# MDR1206AFI register map
Vendor: Milandr; File version: 1.0
CPU: BM-310S0, little endian
Registers are 32-bit, read-write, reset 0x0 unless marked. A register's access mark holds for its fields unless they carry their own. Offsets are from the block's base; [hi:lo] are bit positions; {n}, {i} and the like mark numbered series; 'fields as' and 'values as' point back to an identical list.

## BKP — BKP description
Base 0x50060000
0x00 WPR — WPR description
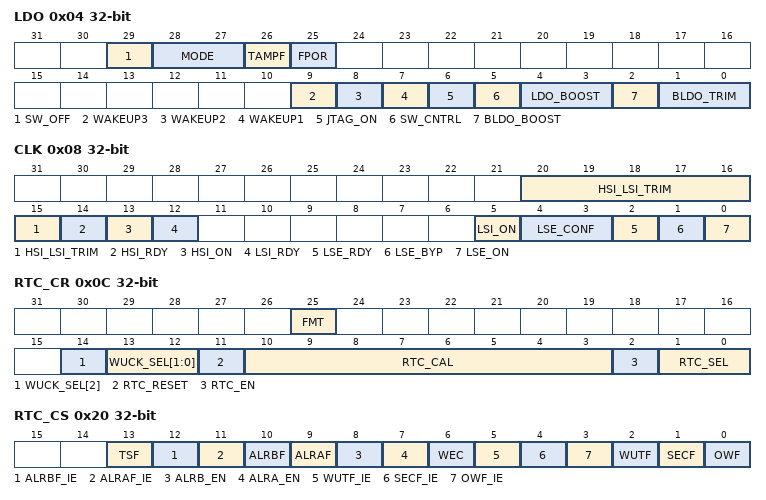
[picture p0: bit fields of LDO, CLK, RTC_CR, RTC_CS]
0x04 LDO — LDO description
  [29] SW_OFF — SW_OFF description
  [28:27] MODE — MODE description
  [26] TAMPF — TAMPF description
  [25] FPOR — FPOR description
  [9] WAKEUP3 ro — WAKEUP3 description
  [8] WAKEUP2 ro — WAKEUP2 description
  [7] WAKEUP1 ro — WAKEUP1 description
  [6] JTAG_ON — JTAG_ON description
  [5] SW_CNTRL — SW_CNTRL description
  [4:3] LDO_BOOST — LDO_BOOST description
  [2] BLDO_BOOST — BLDO_BOOST description
  [1:0] BLDO_TRIM — BLDO_TRIM description
0x08 CLK — CLK description
  [20:15] HSI_LSI_TRIM — HSI_LSI_TRIM description
  [14] HSI_RDY ro — HSI_RDY description
  [13] HSI_ON — HSI_ON description
  [12] LSI_RDY ro — LSI_RDY description
  [5] LSI_ON — LSI_ON description
  [4:3] LSE_CONF — LSE_CONF description
  [2] LSE_RDY ro — LSE_RDY description
  [1] LSE_BYP — LSE_BYP description
  [0] LSE_ON — LSE_ON description
0x0C RTC_CR — RTC_CR description
  [25] FMT — FMT description
  [14] WUCK_SEL[2] — WUCK_SEL[2] description
  [13:12] WUCK_SEL[1:0] — WUCK_SEL[1:0] description
  [11] RTC_RESET — RTC_RESET description
  [10:3] RTC_CAL — RTC_CAL description
  [2] RTC_EN — RTC_EN description
  [1:0] RTC_SEL — RTC_SEL description
0x10 RTC_WUTR — RTC_WUTR description
0x14 RTC_PREDIV_S — RTC_PREDIV_S description
  [19:0] RTC_DIV — RTC_DIV description
0x18 RTC_PRL — RTC_PRL description
  [19:0] RTC_PRL
0x1C RTC_ALRM — RTC_ALRM description
0x20 RTC_CS — RTC_CS description
  [13] TSF — TSF description
  [12] ALRBF_IE — ALRBF_IE description
  [11] ALRAF_IE — ALRAF_IE description
  [10] ALRBF — ALRBF description
  [9] ALRAF — ALRAF description
  [8] ALRB_EN — ALRB_EN description
  [7] ALRA_EN — ALRA_EN description
  [6] WEC ro — WEC description
  [5] WUTF_IE — WUTF_IE description
  [4] SECF_IE — SECF_IE description
  [3] OWF_IE — OWF_IE description
  [2] WUTF — WUTF description
  [1] SECF — SECF description
  [0] OWF — OWF description
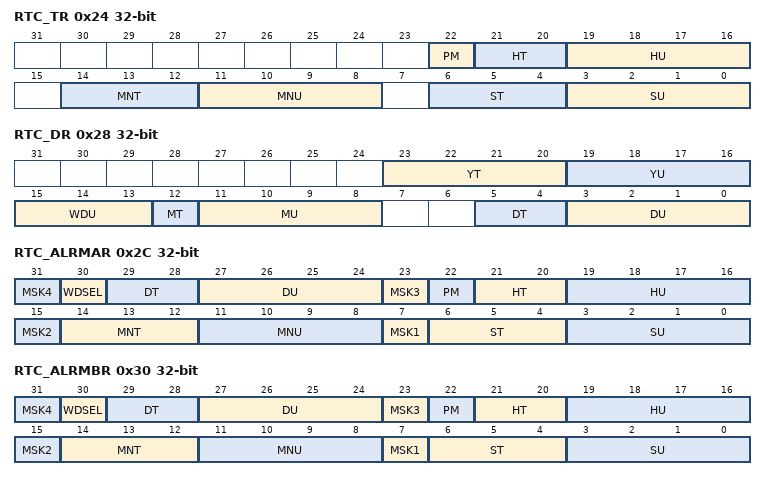
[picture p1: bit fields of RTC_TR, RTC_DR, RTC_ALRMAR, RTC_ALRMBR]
0x24 RTC_TR — RTC_TR description
  [22] PM — PM description
  [21:20] HT — HT description
  [19:16] HU — HU description
  [14:12] MNT — MNT description
  [11:8] MNU — MNU description
  [6:4] ST — ST description
  [3:0] SU — SU description
0x28 RTC_DR — RTC_DR description
  [23:20] YT — YT description
  [19:16] YU — YU description
  [15:13] WDU — WDU description
  [12] MT — MT description
  [11:8] MU — MU description
  [5:4] DT — DT description
  [3:0] DU — DU description
0x2C RTC_ALRMAR — RTC_ALRMAR description
  [8n-1] MSK{n} (n=1..4) — MSK{n} description
  [30] WDSEL — WDSEL description
  [29:28] DT — DT description
  [27:24] DU — DU description
  [22] PM — PM description
  [21:20] HT — HT description
  [19:16] HU — HU description
  [14:12] MNT — MNT description
  [11:8] MNU — MNU description
  [6:4] ST — ST description
  [3:0] SU — SU description
0x30 RTC_ALRMBR — RTC_ALRMBR description
  fields as RTC_ALRMAR
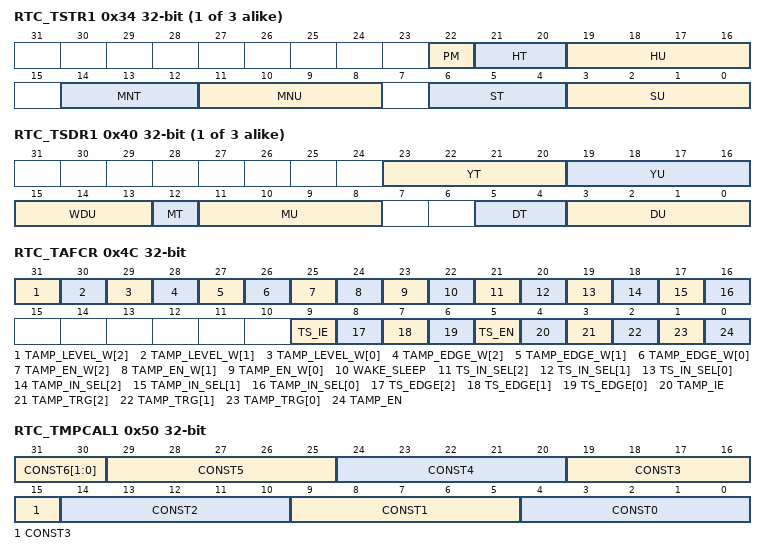
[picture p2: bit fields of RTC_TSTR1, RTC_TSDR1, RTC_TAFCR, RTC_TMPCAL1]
{0x30+4i} RTC_TSTR{i} ro (i=1..3) — RTC_TSTR{i} description
  fields as RTC_TR
{0x3C+4i} RTC_TSDR{i} ro (i=1..3) — RTC_TSDR{i} description
  fields as RTC_DR
0x4C RTC_TAFCR — RTC_TAFCR description
  [31] TAMP_LEVEL_W[2] — TAMP_LEVEL_W[2] description
  [30] TAMP_LEVEL_W[1] — TAMP_LEVEL_W[1] description
  [29] TAMP_LEVEL_W[0] — TAMP_LEVEL_W[0] description
  [28] TAMP_EDGE_W[2] — TAMP_EDGE_W[2] description
  [27] TAMP_EDGE_W[1] — TAMP_EDGE_W[1] description
  [26] TAMP_EDGE_W[0] — TAMP_EDGE_W[0] description
  [25] TAMP_EN_W[2] — TAMP_EN_W[2] description
  [24] TAMP_EN_W[1] — TAMP_EN_W[1] description
  [23] TAMP_EN_W[0] — TAMP_EN_W[0] description
  [22] WAKE_SLEEP — WAKE_SLEEP description
  [21] TS_IN_SEL[2] — TS_IN_SEL[2] description
  [20] TS_IN_SEL[1] — TS_IN_SEL[1] description
  [19] TS_IN_SEL[0] — TS_IN_SEL[0] description
  [18] TAMP_IN_SEL[2] — TAMP_IN_SEL[2] description
  [17] TAMP_IN_SEL[1] — TAMP_IN_SEL[1] description
  [16] TAMP_IN_SEL[0] — TAMP_IN_SEL[0] description
  [9] TS_IE — TS_IE description
  [8] TS_EDGE[2] — TS_EDGE[2] description
  [7] TS_EDGE[1] — TS_EDGE[1] description
  [6] TS_EDGE[0] — TS_EDGE[0] description
  [5] TS_EN — TS_EN description
  [4] TAMP_IE — TAMP_IE description
  [3] TAMP_TRG[2] — TAMP_TRG[2] description
  [2] TAMP_TRG[1] — TAMP_TRG[1] description
  [1] TAMP_TRG[0] — TAMP_TRG[0] description
  [0] TAMP_EN — TAMP_EN description
0x50 RTC_TMPCAL1 — RTC_TMPCAL1 description
  [31:30] CONST6[1:0] — CONST6[1:0] description
  [5n+4:5n] CONST{n} (n=0..5) — CONST{n} description
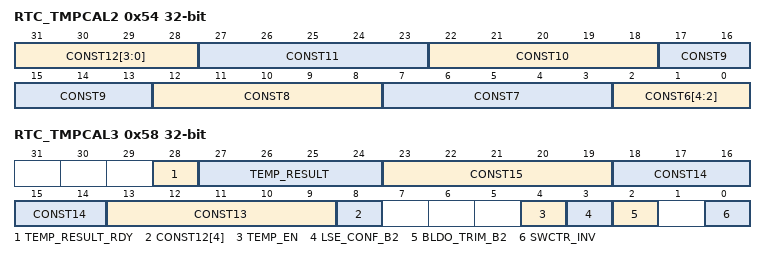
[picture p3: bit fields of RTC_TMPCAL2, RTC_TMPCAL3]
0x54 RTC_TMPCAL2 — RTC_TMPCAL2 description
  [31:28] CONST12[3:0] — CONST12[3:0] description
  [5n-28:5n-32] CONST{n} (n=7..11) — CONST{n} description
  [2:0] CONST6[4:2] — CONST6[4:2] description
0x58 RTC_TMPCAL3 — RTC_TMPCAL3 description
  [28] TEMP_RESULT_RDY ro — TEMP_RESULT_RDY description
  [27:24] TEMP_RESULT ro — TEMP_RESULT description
  [23:19] CONST15 — CONST15 description
  [18:14] CONST14 — CONST14 description
  [13:9] CONST13 — CONST13 description
  [8] CONST12[4] — CONST12[4] description
  [4] TEMP_EN — TEMP_EN description
  [3] LSE_CONF_B2 — LSE_CONF_B2 description
  [2] BLDO_TRIM_B2 — BLDO_TRIM_B2 description
  [0] SWCTR_INV — SWCTR_INV description
